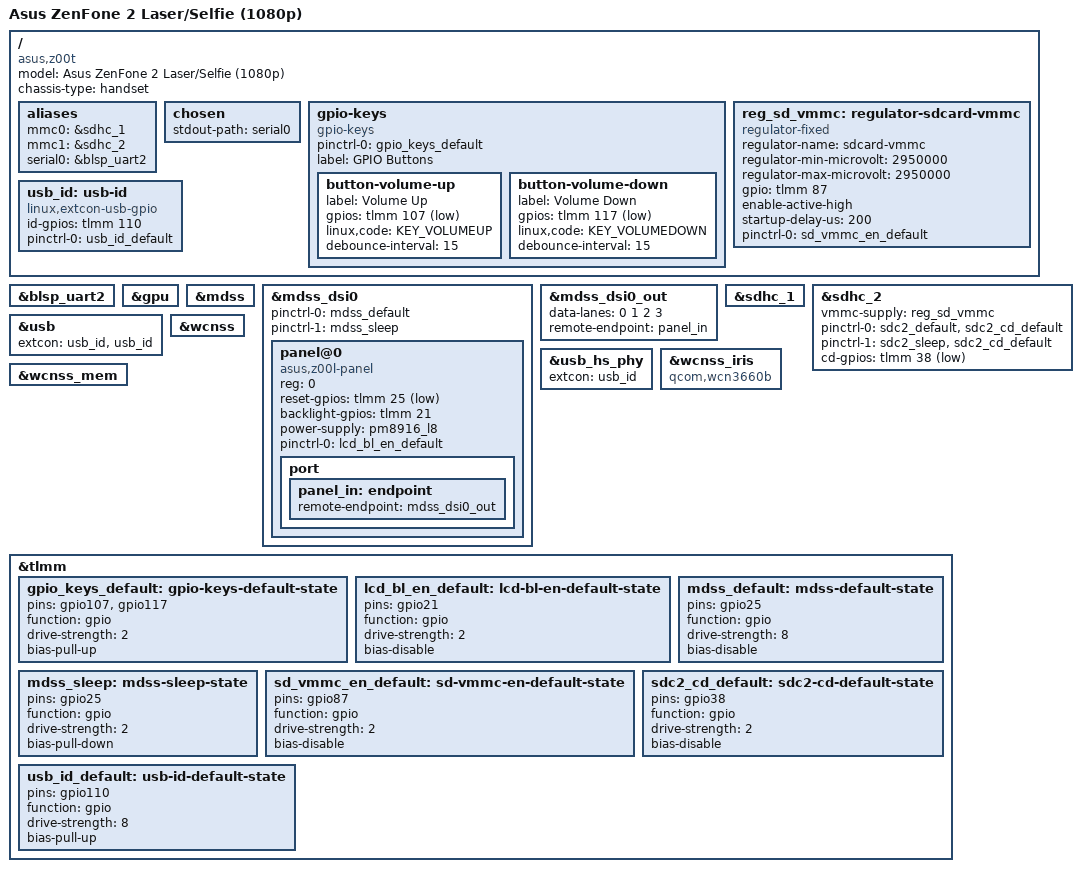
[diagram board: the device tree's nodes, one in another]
/dts-v1/;

#include "msm8939-pm8916.dtsi"
#include <dt-bindings/gpio/gpio.h>
#include <dt-bindings/input/input.h>

/ {
	model = "Asus ZenFone 2 Laser/Selfie (1080p)";
	compatible = "asus,z00t", "qcom,msm8939";
	chassis-type = "handset";

	aliases {
		mmc0 = &sdhc_1;
		mmc1 = &sdhc_2;
		serial0 = &blsp_uart2;
	};

	chosen {
		stdout-path = "serial0";
	};

	gpio-keys {
		compatible = "gpio-keys";

		pinctrl-names = "default";
		pinctrl-0 = <&gpio_keys_default>;

		label = "GPIO Buttons";

		button-volume-up {
			label = "Volume Up";
			gpios = <&tlmm 107 GPIO_ACTIVE_LOW>;
			linux,code = <KEY_VOLUMEUP>;
			debounce-interval = <15>;
		};

		button-volume-down {
			label = "Volume Down";
			gpios = <&tlmm 117 GPIO_ACTIVE_LOW>;
			linux,code = <KEY_VOLUMEDOWN>;
			debounce-interval = <15>;
		};
	};

	reg_sd_vmmc: regulator-sdcard-vmmc {
		compatible = "regulator-fixed";
		regulator-name = "sdcard-vmmc";
		regulator-min-microvolt = <2950000>;
		regulator-max-microvolt = <2950000>;

		gpio = <&tlmm 87 GPIO_ACTIVE_HIGH>;
		enable-active-high;

		startup-delay-us = <200>;

		pinctrl-names = "default";
		pinctrl-0 = <&sd_vmmc_en_default>;
	};

	usb_id: usb-id {
		compatible = "linux,extcon-usb-gpio";
		id-gpios = <&tlmm 110 GPIO_ACTIVE_HIGH>;
		pinctrl-0 = <&usb_id_default>;
		pinctrl-names = "default";
	};
};

&blsp_uart2 {
	status = "okay";
};

&gpu {
	status = "okay";
};

&mdss {
	status = "okay";
};

&mdss_dsi0 {
	pinctrl-names = "default", "sleep";
	pinctrl-0 = <&mdss_default>;
	pinctrl-1 = <&mdss_sleep>;
	status = "okay";

	panel@0 {
		compatible = "asus,z00l-panel";
		reg = <0>;

		reset-gpios = <&tlmm 25 GPIO_ACTIVE_LOW>;
		backlight-gpios = <&tlmm 21 GPIO_ACTIVE_HIGH>;
		power-supply = <&pm8916_l8>;

		pinctrl-names = "default";
		pinctrl-0 = <&lcd_bl_en_default>;

		port {
			panel_in: endpoint {
				remote-endpoint = <&mdss_dsi0_out>;
			};
		};
	};
};

&mdss_dsi0_out {
	data-lanes = <0 1 2 3>;
	remote-endpoint = <&panel_in>;
};

&sdhc_1 {
	status = "okay";
};

&sdhc_2 {
	status = "okay";
	vmmc-supply = <&reg_sd_vmmc>;

	pinctrl-0 = <&sdc2_default &sdc2_cd_default>;
	pinctrl-1 = <&sdc2_sleep &sdc2_cd_default>;
	pinctrl-names = "default", "sleep";
	cd-gpios = <&tlmm 38 GPIO_ACTIVE_LOW>;
};

&usb {
	extcon = <&usb_id>, <&usb_id>;
	status = "okay";
};

&usb_hs_phy {
	extcon = <&usb_id>;
};

&wcnss {
	status = "okay";
};

&wcnss_iris {
	compatible = "qcom,wcn3660b";
};

&wcnss_mem {
	status = "okay";
};

&tlmm {
	gpio_keys_default: gpio-keys-default-state {
		pins = "gpio107", "gpio117";
		function = "gpio";
		drive-strength = <2>;
		bias-pull-up;
	};

	lcd_bl_en_default: lcd-bl-en-default-state {
		pins = "gpio21";
		function = "gpio";

		drive-strength = <2>;
		bias-disable;
	};

	mdss_default: mdss-default-state {
		pins = "gpio25";
		function = "gpio";

		drive-strength = <8>;
		bias-disable;
	};

	mdss_sleep: mdss-sleep-state {
		pins = "gpio25";
		function = "gpio";

		drive-strength = <2>;
		bias-pull-down;
	};

	sd_vmmc_en_default: sd-vmmc-en-default-state {
		pins = "gpio87";
		function = "gpio";
		drive-strength = <2>;
		bias-disable;
	};

	sdc2_cd_default: sdc2-cd-default-state {
		pins = "gpio38";
		function = "gpio";
		drive-strength = <2>;
		bias-disable;
	};

	usb_id_default: usb-id-default-state {
		pins = "gpio110";
		function = "gpio";
		drive-strength = <8>;
		bias-pull-up;
	};
};

